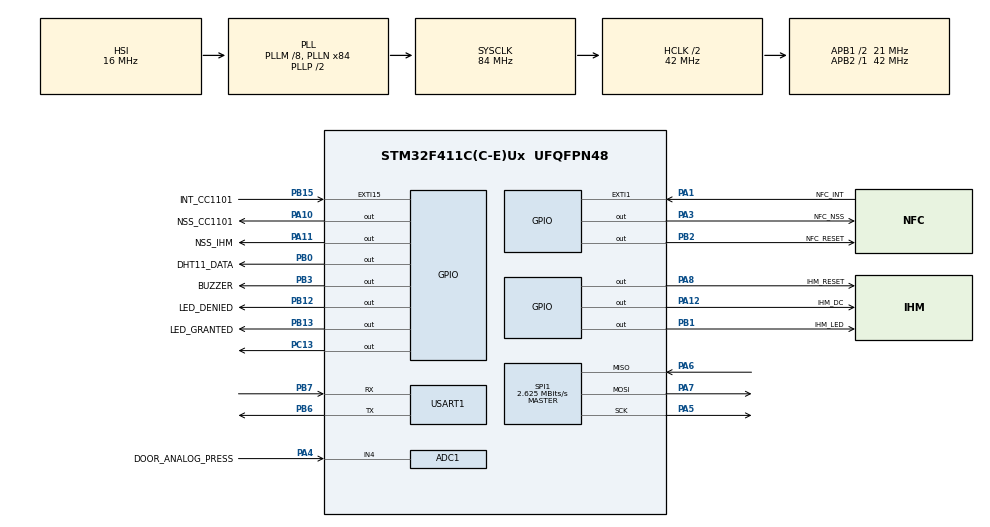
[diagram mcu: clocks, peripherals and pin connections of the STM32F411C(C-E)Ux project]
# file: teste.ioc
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ADC1.Channel-0\#ChannelRegularConversion=ADC_CHANNEL_4
ADC1.NbrOfConversionFlag=1
ADC1.Rank-0\#ChannelRegularConversion=1
ADC1.SamplingTime-0\#ChannelRegularConversion=ADC_SAMPLETIME_3CYCLES
ADC1.master=1
Mcu.Family=STM32F4
Mcu.Name=STM32F411C(C-E)Ux
Mcu.Package=UFQFPN48
NVIC.EXTI15_10_IRQn=true\:0\:0\:false\:false\:true\:true\:true\:true
NVIC.EXTI1_IRQn=true\:0\:0\:false\:false\:true\:true\:true\:true
NVIC.PriorityGroup=NVIC_PRIORITYGROUP_4
NVIC.TIM1_UP_TIM10_IRQn=true\:0\:0\:false\:false\:true\:true\:true\:true
NVIC.USART1_IRQn=true\:0\:0\:false\:false\:true\:true\:true\:true
PA1.GPIO_Label=NFC_INT
PA1.GPIO_ModeDefaultEXTI=GPIO_MODE_IT_FALLING
PA1.GPIO_PuPd=GPIO_PULLUP
PA1.Signal=GPXTI1
PA10.GPIO_Label=NSS_CC1101
PA10.PinState=GPIO_PIN_SET
PA10.Signal=GPIO_Output
PA11.GPIO_Label=NSS_IHM
PA11.Signal=GPIO_Output
PA12.GPIO_Label=IHM_DC
PA12.Signal=GPIO_Output
PA3.GPIO_Label=NFC_NSS
PA3.PinState=GPIO_PIN_SET
PA3.Signal=GPIO_Output
PA4.GPIO_Label=DOOR_ANALOG_PRESS
PA4.Signal=ADCx_IN4
PA5.Mode=Full_Duplex_Master
PA5.Signal=SPI1_SCK
PA6.Mode=Full_Duplex_Master
PA6.Signal=SPI1_MISO
PA7.Mode=Full_Duplex_Master
PA7.Signal=SPI1_MOSI
PA8.GPIO_Label=IHM_RESET
PA8.Signal=GPIO_Output
PB0.GPIO_Label=DHT11_DATA
PB0.GPIO_ModeDefaultOutputPP=GPIO_MODE_OUTPUT_OD
PB0.GPIO_PuPd=GPIO_NOPULL
PB0.GPIO_Speed=GPIO_SPEED_FREQ_HIGH
PB0.Signal=GPIO_Output
PB1.GPIO_Label=IHM_LED
PB1.Signal=GPIO_Output
PB12.GPIO_Label=LED_DENIED
PB12.Signal=GPIO_Output
PB13.GPIO_Label=LED_GRANTED
PB13.Signal=GPIO_Output
PB15.GPIO_Label=INT_CC1101
PB15.GPIO_ModeDefaultEXTI=GPIO_MODE_IT_FALLING
PB15.Signal=GPXTI15
PB2.GPIO_Label=NFC_RESET
PB2.PinState=GPIO_PIN_SET
PB2.Signal=GPIO_Output
PB3.GPIO_Label=BUZZER
PB3.Signal=GPIO_Output
PB6.Mode=Asynchronous
PB6.Signal=USART1_TX
PB7.Mode=Asynchronous
PB7.Signal=USART1_RX
PC13-ANTI_TAMP.Signal=GPIO_Output
PC14-OSC32_IN.Mode=LSE-External-Oscillator
PC14-OSC32_IN.Signal=RCC_OSC32_IN
PC15-OSC32_OUT.Mode=LSE-External-Oscillator
PC15-OSC32_OUT.Signal=RCC_OSC32_OUT
PH0\ -\ OSC_IN.Mode=HSE-External-Clock-Source
PH0\ -\ OSC_IN.Signal=RCC_OSC_IN
PH1\ -\ OSC_OUT.Mode=HSE-External-Clock-Source
PH1\ -\ OSC_OUT.Signal=RCC_OSC_OUT
ProjectManager.HeapSize=0x200
ProjectManager.StackSize=0x400
ProjectManager.TargetToolchain=CMake
RCC.48MHZClocksFreq_Value=42000000
RCC.AHBCLKDivider=RCC_SYSCLK_DIV2
RCC.AHBFreq_Value=42000000
RCC.APB1CLKDivider=RCC_HCLK_DIV2
RCC.APB1Freq_Value=21000000
RCC.APB1TimFreq_Value=42000000
RCC.APB2Freq_Value=42000000
RCC.APB2TimFreq_Value=42000000
RCC.CortexFreq_Value=42000000
RCC.HCLKFreq_Value=42000000
RCC.HSE_VALUE=25000000
RCC.HSI_VALUE=16000000
RCC.PLLM=8
RCC.PLLN=84
RCC.RCC_RTC_Clock_Source=RCC_RTCCLKSOURCE_LSE
RCC.RCC_RTC_Clock_SourceVirtual=RCC_RTCCLKSOURCE_LSE
RCC.SYSCLKFreq_VALUE=84000000
RCC.SYSCLKSource=RCC_SYSCLKSOURCE_PLLCLK
RCC.VCOOutputFreq_Value=168000000
SH.ADCx_IN4.0=ADC1_IN4,IN4
SPI1.BaudRatePrescaler=SPI_BAUDRATEPRESCALER_16
SPI1.CalculateBaudRate=2.625 MBits/s
SPI1.Direction=SPI_DIRECTION_2LINES
SPI1.Mode=SPI_MODE_MASTER
SPI1.VirtualType=VM_MASTER
TIM10.AutoReloadPreload=TIM_AUTORELOAD_PRELOAD_DISABLE
TIM10.Period=2999
TIM10.Prescaler=41999
USART1.VirtualMode=VM_ASYNC
VP_RTC_VS_RTC_Activate.Mode=RTC_Enabled
VP_RTC_VS_RTC_Calendar.Mode=RTC_Calendar
VP_TIM10_VS_ClockSourceINT.Mode=Enable_Timer
board=custom

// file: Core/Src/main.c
/* USER CODE BEGIN Header */
/**
  ******************************************************************************
  * @file           : main.c
  * @brief          : Main program body
  ******************************************************************************
  * @attention
  *
  * Copyright (c) 2026 STMicroelectronics.
  * All rights reserved.
  *
  * This software is licensed under terms that can be found in the LICENSE file
  * in the root directory of this software component.
  * If no LICENSE file comes with this software, it is provided AS-IS.
  *
  ******************************************************************************
  */
/* USER CODE END Header */
#include "main.h"

/* USER CODE BEGIN Includes */
#include "app.h"
/* USER CODE END Includes */

ADC_HandleTypeDef hadc1;

RTC_HandleTypeDef hrtc;

SPI_HandleTypeDef hspi1;

TIM_HandleTypeDef htim10;

UART_HandleTypeDef huart1;

/* USER CODE BEGIN PV */
volatile uint8_t s_rx_ready = 0u;
volatile uint8_t nfc_card_ready = 0u;
/* USER CODE END PV */

void SystemClock_Config(void);
static void MX_GPIO_Init(void);
static void MX_ADC1_Init(void);
static void MX_RTC_Init(void);
static void MX_SPI1_Init(void);
static void MX_USART1_UART_Init(void);
static void MX_TIM10_Init(void);

int main(void)
{

  /* MCU Configuration--------------------------------------------------------*/

  /* Reset of all peripherals, Initializes the Flash interface and the Systick. */
  HAL_Init();

  /* Configure the system clock */
  SystemClock_Config();

  /* Initialize all configured peripherals */
  MX_GPIO_Init();
  MX_ADC1_Init();
  MX_RTC_Init();
  MX_SPI1_Init();
  MX_USART1_UART_Init();
  MX_TIM10_Init();
  /* USER CODE BEGIN 2 */
  APP_Init();
  /* USER CODE END 2 */

  /* Infinite loop */
  while (1)
  {

    /* USER CODE BEGIN 3 */
    APP_Run();
  }
  /* USER CODE END 3 */
}

void SystemClock_Config(void)
{
  RCC_OscInitTypeDef RCC_OscInitStruct = {0};
  RCC_ClkInitTypeDef RCC_ClkInitStruct = {0};

  /** Configure the main internal regulator output voltage
  */
  __HAL_RCC_PWR_CLK_ENABLE();
  __HAL_PWR_VOLTAGESCALING_CONFIG(PWR_REGULATOR_VOLTAGE_SCALE1);

  /** Initializes the RCC Oscillators according to the specified parameters
  * in the RCC_OscInitTypeDef structure.
  */
  RCC_OscInitStruct.OscillatorType = RCC_OSCILLATORTYPE_HSI|RCC_OSCILLATORTYPE_LSE;
  RCC_OscInitStruct.LSEState = RCC_LSE_ON;
  RCC_OscInitStruct.HSIState = RCC_HSI_ON;
  RCC_OscInitStruct.HSICalibrationValue = RCC_HSICALIBRATION_DEFAULT;
  RCC_OscInitStruct.PLL.PLLState = RCC_PLL_ON;
  RCC_OscInitStruct.PLL.PLLSource = RCC_PLLSOURCE_HSI;
  RCC_OscInitStruct.PLL.PLLM = 8;
  RCC_OscInitStruct.PLL.PLLN = 84;
  RCC_OscInitStruct.PLL.PLLP = RCC_PLLP_DIV2;
  RCC_OscInitStruct.PLL.PLLQ = 4;
  if (HAL_RCC_OscConfig(&RCC_OscInitStruct) != HAL_OK)
  {
    Error_Handler();
  }

  /** Initializes the CPU, AHB and APB buses clocks
  */
  RCC_ClkInitStruct.ClockType = RCC_CLOCKTYPE_HCLK|RCC_CLOCKTYPE_SYSCLK
                              |RCC_CLOCKTYPE_PCLK1|RCC_CLOCKTYPE_PCLK2;
  RCC_ClkInitStruct.SYSCLKSource = RCC_SYSCLKSOURCE_PLLCLK;
  RCC_ClkInitStruct.AHBCLKDivider = RCC_SYSCLK_DIV2;
  RCC_ClkInitStruct.APB1CLKDivider = RCC_HCLK_DIV2;
  RCC_ClkInitStruct.APB2CLKDivider = RCC_HCLK_DIV1;

  if (HAL_RCC_ClockConfig(&RCC_ClkInitStruct, FLASH_LATENCY_1) != HAL_OK)
  {
    Error_Handler();
  }
}

static void MX_ADC1_Init(void)
{

  ADC_ChannelConfTypeDef sConfig = {0};

  /** Configure the global features of the ADC (Clock, Resolution, Data Alignment and number of conversion)
  */
  hadc1.Instance = ADC1;
  hadc1.Init.ClockPrescaler = ADC_CLOCK_SYNC_PCLK_DIV2;
  hadc1.Init.Resolution = ADC_RESOLUTION_12B;
  hadc1.Init.ScanConvMode = DISABLE;
  hadc1.Init.ContinuousConvMode = DISABLE;
  hadc1.Init.DiscontinuousConvMode = DISABLE;
  hadc1.Init.ExternalTrigConvEdge = ADC_EXTERNALTRIGCONVEDGE_NONE;
  hadc1.Init.ExternalTrigConv = ADC_SOFTWARE_START;
  hadc1.Init.DataAlign = ADC_DATAALIGN_RIGHT;
  hadc1.Init.NbrOfConversion = 1;
  hadc1.Init.DMAContinuousRequests = DISABLE;
  hadc1.Init.EOCSelection = ADC_EOC_SINGLE_CONV;
  if (HAL_ADC_Init(&hadc1) != HAL_OK)
  {
    Error_Handler();
  }

  /** Configure for the selected ADC regular channel its corresponding rank in the sequencer and its sample time.
  */
  sConfig.Channel = ADC_CHANNEL_4;
  sConfig.Rank = 1;
  sConfig.SamplingTime = ADC_SAMPLETIME_3CYCLES;
  if (HAL_ADC_ConfigChannel(&hadc1, &sConfig) != HAL_OK)
  {
    Error_Handler();
  }

}

static void MX_RTC_Init(void)
{

  RTC_TimeTypeDef sTime = {0};
  RTC_DateTypeDef sDate = {0};

  /** Initialize RTC Only
  */
  hrtc.Instance = RTC;
  hrtc.Init.HourFormat = RTC_HOURFORMAT_24;
  hrtc.Init.AsynchPrediv = 127;
  hrtc.Init.SynchPrediv = 255;
  hrtc.Init.OutPut = RTC_OUTPUT_DISABLE;
  hrtc.Init.OutPutPolarity = RTC_OUTPUT_POLARITY_HIGH;
  hrtc.Init.OutPutType = RTC_OUTPUT_TYPE_OPENDRAIN;
  if (HAL_RTC_Init(&hrtc) != HAL_OK)
  {
    Error_Handler();
  }

  /** Initialize RTC and set the Time and Date
  */
  sTime.Hours = 0x0;
  sTime.Minutes = 0x0;
  sTime.Seconds = 0x0;
  sTime.DayLightSaving = RTC_DAYLIGHTSAVING_NONE;
  sTime.StoreOperation = RTC_STOREOPERATION_RESET;
  if (HAL_RTC_SetTime(&hrtc, &sTime, RTC_FORMAT_BCD) != HAL_OK)
  {
    Error_Handler();
  }
  sDate.WeekDay = RTC_WEEKDAY_MONDAY;
  sDate.Month = RTC_MONTH_JANUARY;
  sDate.Date = 0x1;
  sDate.Year = 0x0;

  if (HAL_RTC_SetDate(&hrtc, &sDate, RTC_FORMAT_BCD) != HAL_OK)
  {
    Error_Handler();
  }

}

static void MX_SPI1_Init(void)
{

  /* SPI1 parameter configuration*/
  hspi1.Instance = SPI1;
  hspi1.Init.Mode = SPI_MODE_MASTER;
  hspi1.Init.Direction = SPI_DIRECTION_2LINES;
  hspi1.Init.DataSize = SPI_DATASIZE_8BIT;
  hspi1.Init.CLKPolarity = SPI_POLARITY_LOW;
  hspi1.Init.CLKPhase = SPI_PHASE_1EDGE;
  hspi1.Init.NSS = SPI_NSS_SOFT;
  hspi1.Init.BaudRatePrescaler = SPI_BAUDRATEPRESCALER_16;
  hspi1.Init.FirstBit = SPI_FIRSTBIT_MSB;
  hspi1.Init.TIMode = SPI_TIMODE_DISABLE;
  hspi1.Init.CRCCalculation = SPI_CRCCALCULATION_DISABLE;
  hspi1.Init.CRCPolynomial = 10;
  if (HAL_SPI_Init(&hspi1) != HAL_OK)
  {
    Error_Handler();
  }

}

static void MX_TIM10_Init(void)
{

  htim10.Instance = TIM10;
  htim10.Init.Prescaler = 41999;
  htim10.Init.CounterMode = TIM_COUNTERMODE_UP;
  htim10.Init.Period = 2999;
  htim10.Init.ClockDivision = TIM_CLOCKDIVISION_DIV1;
  htim10.Init.AutoReloadPreload = TIM_AUTORELOAD_PRELOAD_DISABLE;
  if (HAL_TIM_Base_Init(&htim10) != HAL_OK)
  {
    Error_Handler();
  }

}

static void MX_USART1_UART_Init(void)
{

  huart1.Instance = USART1;
  huart1.Init.BaudRate = 115200;
  huart1.Init.WordLength = UART_WORDLENGTH_8B;
  huart1.Init.StopBits = UART_STOPBITS_1;
  huart1.Init.Parity = UART_PARITY_NONE;
  huart1.Init.Mode = UART_MODE_TX_RX;
  huart1.Init.HwFlowCtl = UART_HWCONTROL_NONE;
  huart1.Init.OverSampling = UART_OVERSAMPLING_16;
  if (HAL_UART_Init(&huart1) != HAL_OK)
  {
    Error_Handler();
  }

}

static void MX_GPIO_Init(void)
{
  GPIO_InitTypeDef GPIO_InitStruct = {0};

  /* GPIO Ports Clock Enable */
  __HAL_RCC_GPIOC_CLK_ENABLE();
  __HAL_RCC_GPIOH_CLK_ENABLE();
  __HAL_RCC_GPIOA_CLK_ENABLE();
  __HAL_RCC_GPIOB_CLK_ENABLE();

  /*Configure GPIO pin Output Level */
  HAL_GPIO_WritePin(GPIOC, GPIO_PIN_13, GPIO_PIN_RESET);

  /*Configure GPIO pin Output Level */
  HAL_GPIO_WritePin(GPIOA, NFC_NSS_Pin|NSS_CC1101_Pin, GPIO_PIN_SET);

  /*Configure GPIO pin Output Level */
  HAL_GPIO_WritePin(GPIOB, DHT11_DATA_Pin|IHM_LED_Pin|LED_DENIED_Pin|LED_GRANTED_Pin
                          |BUZZER_Pin, GPIO_PIN_RESET);

  /*Configure GPIO pin Output Level */
  HAL_GPIO_WritePin(NFC_RESET_GPIO_Port, NFC_RESET_Pin, GPIO_PIN_SET);

  /*Configure GPIO pin Output Level */
  HAL_GPIO_WritePin(GPIOA, IHM_RESET_Pin|NSS_IHM_Pin|IHM_DC_Pin, GPIO_PIN_RESET);

  /*Configure GPIO pin : PC13 */
  GPIO_InitStruct.Pin = GPIO_PIN_13;
  GPIO_InitStruct.Mode = GPIO_MODE_OUTPUT_PP;
  GPIO_InitStruct.Pull = GPIO_NOPULL;
  GPIO_InitStruct.Speed = GPIO_SPEED_FREQ_LOW;
  HAL_GPIO_Init(GPIOC, &GPIO_InitStruct);

  /*Configure GPIO pin : NFC_INT_Pin */
  GPIO_InitStruct.Pin = NFC_INT_Pin;
  GPIO_InitStruct.Mode = GPIO_MODE_IT_FALLING;
  GPIO_InitStruct.Pull = GPIO_PULLUP;
  HAL_GPIO_Init(NFC_INT_GPIO_Port, &GPIO_InitStruct);

  /*Configure GPIO pins : NFC_NSS_Pin IHM_RESET_Pin NSS_CC1101_Pin NSS_IHM_Pin
                           IHM_DC_Pin */
  GPIO_InitStruct.Pin = NFC_NSS_Pin|IHM_RESET_Pin|NSS_CC1101_Pin|NSS_IHM_Pin
                          |IHM_DC_Pin;
  GPIO_InitStruct.Mode = GPIO_MODE_OUTPUT_PP;
  GPIO_InitStruct.Pull = GPIO_NOPULL;
  GPIO_InitStruct.Speed = GPIO_SPEED_FREQ_LOW;
  HAL_GPIO_Init(GPIOA, &GPIO_InitStruct);

  /*Configure GPIO pin : DHT11_DATA_Pin */
  GPIO_InitStruct.Pin = DHT11_DATA_Pin;
  GPIO_InitStruct.Mode = GPIO_MODE_OUTPUT_OD;
  GPIO_InitStruct.Pull = GPIO_NOPULL;
  GPIO_InitStruct.Speed = GPIO_SPEED_FREQ_HIGH;
  HAL_GPIO_Init(DHT11_DATA_GPIO_Port, &GPIO_InitStruct);

  /*Configure GPIO pins : IHM_LED_Pin NFC_RESET_Pin LED_DENIED_Pin LED_GRANTED_Pin
                           BUZZER_Pin */
  GPIO_InitStruct.Pin = IHM_LED_Pin|NFC_RESET_Pin|LED_DENIED_Pin|LED_GRANTED_Pin
                          |BUZZER_Pin;
  GPIO_InitStruct.Mode = GPIO_MODE_OUTPUT_PP;
  GPIO_InitStruct.Pull = GPIO_NOPULL;
  GPIO_InitStruct.Speed = GPIO_SPEED_FREQ_LOW;
  HAL_GPIO_Init(GPIOB, &GPIO_InitStruct);

  /*Configure GPIO pin : INT_CC1101_Pin */
  GPIO_InitStruct.Pin = INT_CC1101_Pin;
  GPIO_InitStruct.Mode = GPIO_MODE_IT_FALLING;
  GPIO_InitStruct.Pull = GPIO_NOPULL;
  HAL_GPIO_Init(INT_CC1101_GPIO_Port, &GPIO_InitStruct);

  /* EXTI interrupt init*/
  HAL_NVIC_SetPriority(EXTI1_IRQn, 0, 0);
  HAL_NVIC_EnableIRQ(EXTI1_IRQn);

  HAL_NVIC_SetPriority(EXTI15_10_IRQn, 0, 0);
  HAL_NVIC_EnableIRQ(EXTI15_10_IRQn);

}

/* USER CODE BEGIN 4 */
int __io_putchar(int ch)
{
  HAL_UART_Transmit(&huart1, (uint8_t *)&ch, 1, 0xFFFF);
  return ch;
}

void HAL_GPIO_EXTI_Callback(uint16_t GPIO_Pin)
{
  if (GPIO_Pin == INT_CC1101_Pin) s_rx_ready      = 1u;
  if (GPIO_Pin == NFC_INT_Pin)    nfc_card_ready  = 1u;
}
/* USER CODE END 4 */

void Error_Handler(void)
{
  __disable_irq();
  while (1) {}
}
